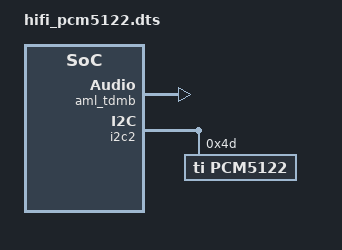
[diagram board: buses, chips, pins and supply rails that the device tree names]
/dts-v1/;
/plugin/;

/ {
	fragment@0 {
		target = <&aml_tdmb>;
		__overlay__ {
			status = "okay";
			pinctrl-names = "tdm_pins";
			pinctrl-0 = <&tdmb_mclk &tdmout_b &tdmin_b>;
		};
	};

	fragment@1 {
		// i2c2 aliased with i2c0.
		target = <&i2c2>;

		__overlay__ {
			status = "okay";

			#address-cells = <1>;
			#size-cells = <0>;

			pcm5122: pcm5122@4d {
				compatible = "ti,pcm5122";
				reg = <0x4d>;
				#sound-dai-cells = <0>;
				status = "okay";
			};
		};
	};

	fragment@2 {
		target = <&tdmbcodec>;

		__overlay__ {
			sound-dai = <&pcm5122 &dummy_codec>;
		};
	};
};
